# netx90_app register map
File version: 1.0
CPU: CM4 r0p1, little endian, MPU, FPU, 4 interrupt priority bits, 78 interrupts
Registers are 32-bit, read-write, reset 0x0 unless marked. A register's access mark holds for its fields unless they carry their own. Offsets are from the block's base; [hi:lo] are bit positions; {n}, {i} and the like mark numbered series; 'fields as' and 'values as' point back to an identical list; <NAME> marks a mode.

## eth
Base 0xFF480000
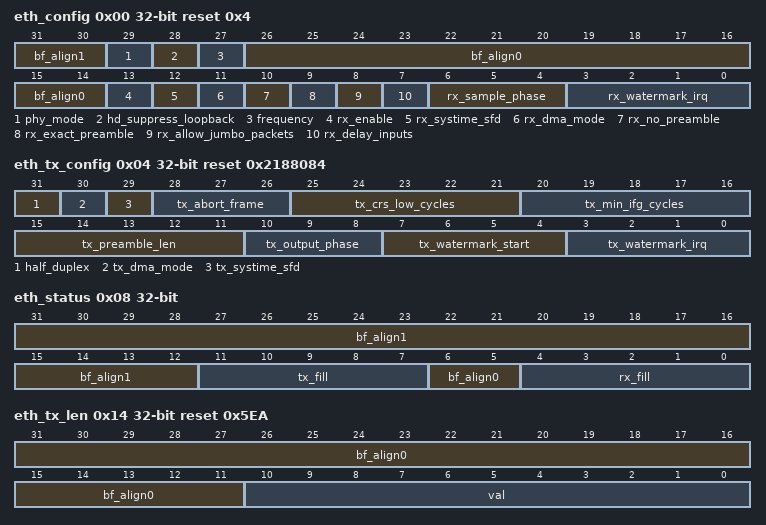
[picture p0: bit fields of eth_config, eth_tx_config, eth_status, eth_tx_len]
0x00 eth_config reset 0x4 (reset mask 0x38003FFF)
  [31:30] bf_align1 — bitField alignment value for aeabi compatibility
  [29] phy_mode — PHY mode: 0: behave like an ethernet MAC, sync to external rxclk/txclk 1: behave like an ethernet PHY, generate txclk (=rxclk), signals change their function: { | rxclk: not used rxd[3:0]: data input, to be connected to txd[3:0] of MAC device rxdv: Data valid input, to be connected to txen of MAC device rxer: Error input, to be connected to txer of MAC device txclk: Clock output, to be connected to rxclk and txclk of MAC device txd[3:0]: Data output, to be connected to rxd[3:0] of MAC device txen: Data valid output, to be connected to rxdv of MAC device txer: Error output. to be connected to rxer of MAC device col: not used crs: not used}
  [28] hd_suppress_loopback — Suppress loopback in half_duplex mode: 1: don't start RX-process, if txen is active. 0: RX and TX work indepentently.
  [27] frequency — MII clock frequency: 1: 50MHz (use in PHY mode only) 0: 25MHz
  [26:14] bf_align0 — bitField alignment value for aeabi compatibility
  [13] rx_enable — Enable of receive state machine: When disabled, receive state machine is reset. After enabling, receive state machine waits for rxdv going down. If rxdv is already down, proper IFG is expected.
  [12] rx_systime_sfd — Sample systime at SFD of received frame: 1: Sample systime_ns to eth_rx_systime_ns at SFD (+constant offset) 0: Sample systime_ns to eth_rx_systime_ns when rxdv gets active (+constant offset)
  [11] rx_dma_mode — Receive DMA mode: Each received frame needs 2 DMA-transfers, one for package data and one for rx_len/status. In rx_dma_mode irq_raw-rx_frame_finished is reset automatically.
  [10] rx_no_preamble — receive starts, when rxdv gets active
  [9] rx_exact_preamble — Accept only packages with exact preamble, rx_preamble_error IRQ will be generated independant on this setting.
  [8] rx_allow_jumbo_packets — Receive frames > 1522 bytes. If jumbo_packets are not allowed, the receive frame buffer must be 1524 bytes. Warning: Frames with len > 2047 will be received, but rx_frame_len has only 11 bit.
  [7] rx_delay_inputs — Delay mii inputs (rx_d, rx_dv, rx_err, crs, col) by 1 clockcycle before sampling them. This leads to inputs fitting to sampled rxclk. Enable this in MAC mode, disable in PHY mode.
  [6:4] rx_sample_phase — clk-phase in which rxd is sampled: PHY mode (phy_mode=1): { | 0,4: sample at posedge tx_clk 1,5: sample at posedge tx_clk + 1cc 2,6: sample at posedge tx_clk + 2cc 3,7: sample at posedge tx_clk + 3cc} MAC mode (phy_mode=0): { | 0: sample at posedge rx_clk + 1cc 1: sample at posedge rx_clk + 2cc 2: sample at posedge rx_clk + 3cc 3: sample at posedge rx_clk + 4cc 4: sample at negedge rx_clk + 3cc 5: sample at negedge rx_clk + 4cc 6: sample at negedge rx_clk + 1cc 7: sample at negedge rx_clk + 2cc}
  [3:0] rx_watermark_irq — Watermark for RX-FIFO, that generates interrupt This number of DWords is available inside RX-FIFO
0x04 eth_tx_config reset 0x2188084 — ETH config register
  [31] half_duplex — Half Duplex Mode: 1: In half duplex mode transmission of a frame starts after the following sequence: - tx_watermark_start was reached - mii_crs became low and stayed low for tx_crs_low_cycles - (tx_min_ifg_cycles - tx_crs_low_cycles) are passed 0: In full duplex mode transmission of a frame starts after the following sequence: - tx_min_ifg_cycles are passed after the last transmitted frame - tx_watermark_start was reached
  [30] tx_dma_mode — In tx_dma_mode tx_len comes from DMAC automatically. An extra tx_lsreq will be generated to request tx_len, before frame data is requested (and after previous frame is finished). In tx_dma_mode irq_raw-tx_frame_finished is reset automatically.
  [29] tx_systime_sfd — Sample systime at SFD: 1: Sample systime_ns to eth_tx_systime_ns at SFD (-constant offset) 0: Sample systime_ns to eth_tx_systime_ns when txen gets active (-constant offset)
  [28:26] tx_abort_frame — Different abort mechanisms: 000: no abort: Transmit frame from TX-FIFO until tx_len and append correct FCS. 001: standard abort: Abort transmission, send wrong FCS, activate mii_txer. SW should keep bit active until irq-tx_frame_finished, then reset TX-FIFO. 010: abort with dribble nibble: Like standard abort, but append dribble nibble after wrong FCS (needed by some PHYs to detect error condition) SW should keep bit active until irq-tx_frame_finished, then reset TX-FIFO. 011: no FCS mode: Transmit frame from TX-FIFO until tx_len but do not append FCS. Never activate mii_txer (except in case of tx_fifo_undr). 100: Fast Track Switching controlled abort: Wait for next byte-border, then attach special FCS as wrong FCS. Special FCS is 'a0a0a0a0', or 'a0a0a0a1' in case that real FCS would end with 'a0'. Do not activate mii_txer. SW should keep bit active until irq-tx_frame_finished, then reset TX-FIFO. 101: reserved 110: reserved 111: reserved
  [25:21] tx_crs_low_cycles — txclk-cycles with mii_crs low, before free carrier is detected (only used in half_duplex mode): Value range: [0,tx_min_ifg_cycles]. For details s. half_duplex mode.
  [20:16] tx_min_ifg_cycles — minimum IFG in txclk-cycles In half_duplex mode reduce value by 2 to compensate cycles for sampling of mii_crs.
  [15:11] tx_preamble_len — Length of TX-preamble in nibbles (incl. SFD)
  [10:8] tx_output_phase — clk-phase in which txd, txen, txer is changed at output PHY mode (phy_mode=1): { | 0,4: change output at negedge tx_clk 1,5: change output at negedge tx_clk + 1cc 2,6: change output at negedge tx_clk + 2cc 3,7: change output at negedge tx_clk + 3cc} MAC mode (phy_mode=0): { | 0: change output at posedge tx_clk + 2cc 1: change output at posedge tx_clk + 3cc 2: change output at posedge tx_clk + 4cc 3: change output at posedge tx_clk + 5cc 4: change output at negedge tx_clk + 4cc 5: change output at negedge tx_clk + 5cc 6: change output at negedge tx_clk + 2cc 7: change output at negedge tx_clk + 3cc}
  [7:4] tx_watermark_start — Watermark for TX-FIFO, that starts transmission. This number of DWords is inside TX-FIFO
  [3:0] tx_watermark_irq — Watermark for TX-FIFO, that generates IRQ. This number of DWords is free inside TX-FIFO
0x08 eth_status ro (reset mask 0xF9F)
  [31:12] bf_align1 — bitField alignment value for aeabi compatibility
  [11:7] tx_fill — Fill-level of TX-FIFO
  [6:5] bf_align0 — bitField alignment value for aeabi compatibility
  [4:0] rx_fill — Fill-level of RX-FIFO
0x0C eth_tx_data — Data to TX-FIFO: returns 0xdeadbeef on read
  [31:0] val — data to TX-FIFO
0x10 eth_rx_data ro — Data from RX-FIFO:
  [31:0] val — data from RX-FIFO
0x14 eth_tx_len reset 0x5EA (reset mask 0x7FF) — Length of data inside transmitted frame (between SFD and FCS) Note: Set this value after previous frame is completely transmitted (irq-tx_frame_finished).
  [31:11] bf_align0 — bitField alignment value for aeabi compatibility
  [10:0] val — To be transmitted data length (excluding SFD and excluding FCS)
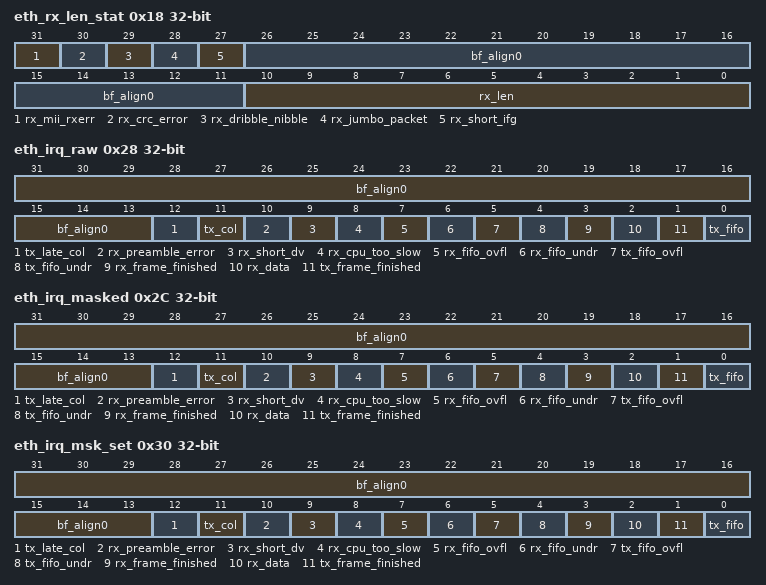
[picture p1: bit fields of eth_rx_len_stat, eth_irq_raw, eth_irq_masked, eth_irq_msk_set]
0x18 eth_rx_len_stat ro (reset mask 0xF80007FF) — Length and status information of lastly received frame
  [31] rx_mii_rxerr — external rxerr signal was active in last frame
  [30] rx_crc_error — wrong RX FCS detected
  [29] rx_dribble_nibble — frame finished at non-even nibble count, last nibble was dropped
  [28] rx_jumbo_packet — rx_frame_len > 1522 detected: In case of eth_config-allow_jumbo_packets=1, this frame was received, but rx_len will overflow at 2048. In case of eth_config-allow_jumbo_packets=0, frame is stopped after 1522, but other status information (rxerr, crc, dribble_nibble) will be checked anyway.
  [27] rx_short_ifg — IFG shorter 960ns detected (preceeding this frame).
  [26:11] bf_align0 — bitField alignment value for aeabi compatibility
  [10:0] rx_len — Received data (excluding SFD and including FCS)
0x20 eth_rx_systime_ns ro — Systime_ns sampled at start of received frame. Exact position of start of frame is defined in eth_config-systime_sfd.
  [31:0] val — Sampled systime_ns
0x24 eth_tx_systime_ns ro — Systime_ns sampled at start of transmitted frame. Exact position of start of frame is defined in eth_tx_config-systime_sfd.
  [31:0] val — Sampled systime_ns
0x28 eth_irq_raw (reset mask 0x1FFF) — Raw IRQ: Read access shows status of unmasked IRQs. IRQs are set automatically and reset by writing to this register: Write access with '1' resets the appropriate IRQ. Write access with '0' does not influence this bit. Write access with '1' to rx_/tx_fifo_undr/_ovfl resets RX-FIFO/TX-FIFO. Bits rx_data and tx_fifo are cleared by reading from/filling the appropriate FIFO.
  [31:13] bf_align0 — bitField alignment value for aeabi compatibility
  [12] tx_late_col — late colision detected in half_duplex mode, started sending jam
  [11] tx_col — collision detected in half_duplex mode, started sending jam
  [10] rx_preamble_error — data <> 0x5 during preamble or wrong length of preamble
  [9] rx_short_dv — mii_rxdv becomes low before SFD
  [8] rx_cpu_too_slow — next frame started before irq_raw_rx_frame_finished was cleared
  [7] rx_fifo_ovfl — RX-FIFO overflow
  [6] rx_fifo_undr — RX-FIFO underrun (debug only, can never happen in ASIC)
  [5] tx_fifo_ovfl — TX-FIFO overflow (debug only, can never happen in ASIC)
  [4] tx_fifo_undr — TX-FIFO underrun
  [3] rx_frame_finished — RX frame finished: Clearing this bit tells the module, that the CPU has read rx_len_stat and the next frame can be received. In rx_dma_mode this bit is handled automatically, demask it to the CPU.
  [2] rx_data — RX Data is available
  [1] tx_frame_finished — TX frame finished: In tx_dma_mode this bit is handled automatically, demask it to the CPU.
  [0] tx_fifo — TX-FIFO has free entries
0x2C eth_irq_masked ro (reset mask 0x1FFF) — Masked IRQ: Shows status of masked IRQs as connected to ARM/xPIC.
  [31:13] bf_align0 — bitField alignment value for aeabi compatibility
  [12] tx_late_col — late colision detected in half_duplex mode, started sending jam
  [11] tx_col — collision detected in half_duplex mode, started sending jam
  [10] rx_preamble_error — data <> 0x5 during preamble or wrong length of preamble
  [9] rx_short_dv — mii_rxdv becomes low before SFD
  [8] rx_cpu_too_slow — next frame started before irq_raw_rx_frame_finished was cleared
  [7] rx_fifo_ovfl — RX-FIFO overflow
  [6] rx_fifo_undr — RX-FIFO underrun (debug only, can never happen in ASIC)
  [5] tx_fifo_ovfl — TX-FIFO overflow (debug only, can never happen in ASIC)
  [4] tx_fifo_undr — TX-FIFO underrun
  [3] rx_frame_finished
  [2] rx_data — RX Data is available
  [1] tx_frame_finished
  [0] tx_fifo — TX-FIFO has free entries
0x30 eth_irq_msk_set (reset mask 0x1FFF) — IRQ mask set: The IRQ mask enables interrupt requests for corresponding interrupt sources. As its bits might be changed by different software tasks, the IRQ mask register is not writable directly, but by set and reset masks: Write access with '1' sets interrupt mask bit. Write access with '0' does not influence this bit. Read access shows actual interrupt mask. Attention: Before activating interrupt mask, delete old pending interrupts by writing the same value to adr_eth_irq_raw.
  fields as eth_irq_masked
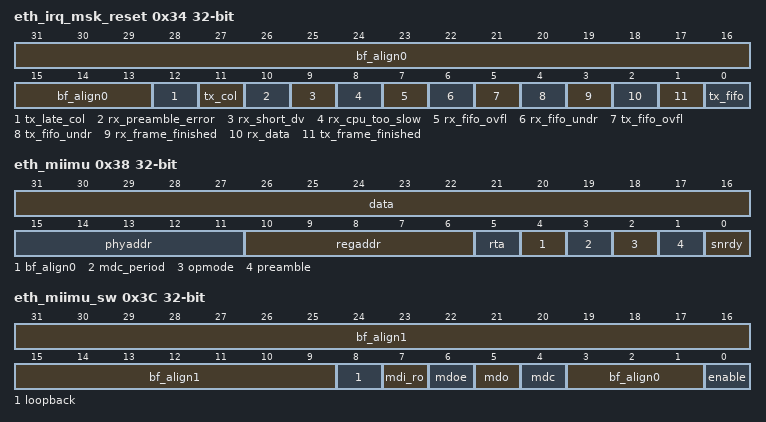
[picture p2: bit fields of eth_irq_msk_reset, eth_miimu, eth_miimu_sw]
0x34 eth_irq_msk_reset (reset mask 0x1FFF) — IRQ mask reset: This is the corresponding reset mask to disable interrupt requests for corresponding interrupt sources: Write access with '1' resets interrupt mask bit. Write access with '0' does not influence this bit. Read access shows actual interrupt mask.
  fields as eth_irq_masked
0x38 eth_miimu (reset mask 0xFFFFFFEF) — MDIO FSM interface controlling for netX external PHY. Note: Loopback for purpose is provided by miimu_sw register and also performed in non-software-mode when enabled. Note: Prior phy_nres-bit was removed. PHY reset must be done by register ASIC_CTRL.phy_control.
  [31:16] data — Data to or from PHY register
  [15:11] phyaddr — PHY address
  [10:6] regaddr — Register address
  [5] rta — Read Turn Around field: 0: one bit 1: two bits
  [4] bf_align0 — bitField alignment value for aeabi compatibility
  [3] mdc_period — MDC period: 1: 800ns 0: 400ns
  [2] opmode — Operation mode: 1: write 0: read
  [1] preamble — Send preamble
  [0] snrdy — Start not ready
0x3C eth_miimu_sw (reset mask 0x1F1) — MDIO software interface controlling for netX internal PHY. Note: Function is similar to old MIIMU unit register 'miimu_sw', however data output enable was removed as it is not necessary for MDIO interface to internal PHY (due to non-bidirectional data signal).
  [31:9] bf_align1 — bitField alignment value for aeabi compatibility
  [8] loopback — MDIO-data-out to data-in loopback for test purpose. 0: no loopback, MDIO-data-in comes from internal PHY. 1: loopback, MDIO-data-in comes from current MDIO-data-out. Note: Loopback can also be used in non-software-mode.
  [7] mdi_ro — current MDI value
  [6] mdoe — MDOE value for software mode
  [5] mdo — MDO value for software mode
  [4] mdc — MDC value for software mode
  [3:1] bf_align0 — bitField alignment value for aeabi compatibility
  [0] enable — Enables software mode: MDC, MDO and MDOE are set by software.
